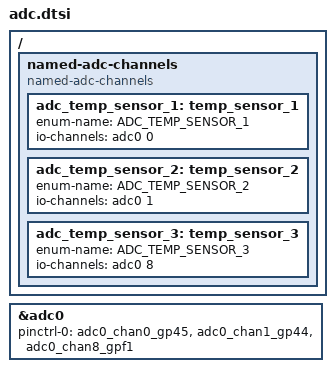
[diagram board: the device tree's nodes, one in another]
/* Copyright 2025 The ChromiumOS Authors
 * Use of this source code is governed by a BSD-style license that can be
 * found in the LICENSE file.
 */

/ {
	named-adc-channels {
		compatible = "named-adc-channels";

		adc_temp_sensor_1: temp_sensor_1 {
			enum-name = "ADC_TEMP_SENSOR_1";
			io-channels = <&adc0 0>;
		};
		adc_temp_sensor_2: temp_sensor_2 {
			enum-name = "ADC_TEMP_SENSOR_2";
			io-channels = <&adc0 1>;
		};
		adc_temp_sensor_3: temp_sensor_3 {
			enum-name = "ADC_TEMP_SENSOR_3";
			io-channels = <&adc0 8>;
		};
	};
};

&adc0 {
	status = "okay";
	pinctrl-0 = <&adc0_chan0_gp45
		     &adc0_chan1_gp44
		     &adc0_chan8_gpf1>;
	pinctrl-names = "default";
};
